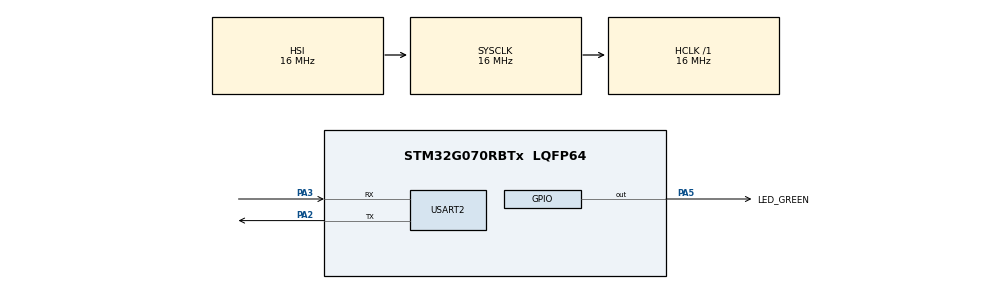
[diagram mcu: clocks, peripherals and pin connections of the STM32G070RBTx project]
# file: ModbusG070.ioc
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FREERTOS.Tasks01=defaultTask,24,128,StartDefaultTask,Default,NULL,Dynamic,NULL,NULL
FREERTOS.configUSE_NEWLIB_REENTRANT=1
Mcu.Family=STM32G0
Mcu.Name=STM32G070RBTx
Mcu.Package=LQFP64
NVIC.TIM17_IRQn=true\:3\:0\:false\:false\:true\:false\:false\:true\:true
NVIC.TimeBase=TIM17_IRQn
NVIC.TimeBaseIP=TIM17
NVIC.USART2_IRQn=true\:3\:0\:false\:false\:true\:true\:true\:true\:true
PA13.GPIO_Label=TMS
PA13.Mode=Serial_Wire
PA13.Signal=SYS_SWDIO
PA14-BOOT0.GPIO_Label=TCK
PA14-BOOT0.Mode=Serial_Wire
PA14-BOOT0.Signal=SYS_SWCLK
PA2.GPIO_PuPd=GPIO_PULLUP
PA2.Mode=Asynchronous
PA2.Signal=USART2_TX
PA3.GPIO_PuPd=GPIO_PULLUP
PA3.Mode=Asynchronous
PA3.Signal=USART2_RX
PA5.GPIO_Label=LED_GREEN
PA5.GPIO_Speed=GPIO_SPEED_FREQ_HIGH
PA5.Signal=GPIO_Output
PC13.Mode=SYS_WakeUp1
PC13.Signal=SYS_WKUP2
PC14-OSC32_IN\ (PC14).Mode=LSE-External-Oscillator
PC14-OSC32_IN\ (PC14).Signal=RCC_OSC32_IN
PC15-OSC32_OUT\ (PC15).Mode=LSE-External-Oscillator
PC15-OSC32_OUT\ (PC15).Signal=RCC_OSC32_OUT
PF0-OSC_IN\ (PF0).GPIO_Label=MCO
PF0-OSC_IN\ (PF0).Mode=HSE-External-Clock-Source
PF0-OSC_IN\ (PF0).Signal=RCC_OSC_IN
ProjectManager.HeapSize=0x200
ProjectManager.StackSize=0x400
ProjectManager.TargetToolchain=STM32CubeIDE
RCC.AHBFreq_Value=16000000
RCC.CortexFreq_Value=16000000
RCC.EXTERNAL_CLOCK_VALUE=12288000
RCC.HCLKFreq_Value=16000000
RCC.HSE_VALUE=8000000
RCC.HSI_VALUE=16000000
RCC.SYSCLKFreq_VALUE=16000000
RCC.VCOOutputFreq_Value=128000000
USART2.VirtualMode-Asynchronous=VM_ASYNC
USART2.WordLength=WORDLENGTH_8B
VP_FREERTOS_VS_CMSIS_V2.Mode=CMSIS_V2
VP_SYS_VS_DBSignals.Mode=DisableDeadBatterySignals
VP_SYS_VS_tim17.Mode=TIM17
board=NUCLEO-G070RB

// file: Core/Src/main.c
/* USER CODE BEGIN Header */
/**
  ******************************************************************************
  * @file           : main.c
  * @brief          : Main program body
  ******************************************************************************
  * @attention
  *
  * Copyright (c) 2024 STMicroelectronics.
  * All rights reserved.
  *
  * This software is licensed under terms that can be found in the LICENSE file
  * in the root directory of this software component.
  * If no LICENSE file comes with this software, it is provided AS-IS.
  *
  ******************************************************************************
  */
/* USER CODE END Header */
#include "main.h"
#include "cmsis_os.h"
#include "usart.h"
#include "gpio.h"

/* USER CODE BEGIN Includes */
#include "Modbus.h"
/* USER CODE END Includes */

/* USER CODE BEGIN PV */
modbusHandler_t ModbusH;
uint16_t ModbusDATA[8];
/* USER CODE END PV */

void SystemClock_Config(void);
void MX_FREERTOS_Init(void);

int main(void)
{

  /* MCU Configuration--------------------------------------------------------*/

  /* Reset of all peripherals, Initializes the Flash interface and the Systick. */
  HAL_Init();

  /* Configure the system clock */
  SystemClock_Config();

  /* Initialize all configured peripherals */
  MX_GPIO_Init();
  MX_USART2_UART_Init();
  /* USER CODE BEGIN 2 */

  //Modbus Slave initialization

  ModbusH.uModbusType = MB_SLAVE;
  ModbusH.port =  &huart2;
  ModbusH.u8id = 1; // For master it must be 0
  ModbusH.u16timeOut = 1000;
  ModbusH.EN_Port = NULL;
  ModbusH.EN_Port = NULL;
  ModbusH.EN_Pin = 0;
  ModbusH.u16regs = ModbusDATA;
  ModbusH.u16regsize= sizeof(ModbusDATA)/sizeof(ModbusDATA[0]);
  ModbusH.xTypeHW = USART_HW;

  //Initialize Modbus library
  ModbusInit(&ModbusH);
  //Start capturing traffic on serial Port
  ModbusStart(&ModbusH);

  /* USER CODE END 2 */

  /* Init scheduler */
  osKernelInitialize();

  /* Call init function for freertos objects (in freertos.c) */
  MX_FREERTOS_Init();

  /* Start scheduler */
  osKernelStart();

  /* We should never get here as control is now taken by the scheduler */
  /* Infinite loop */
  while (1)
  {

  }
}

void SystemClock_Config(void)
{
  RCC_OscInitTypeDef RCC_OscInitStruct = {0};
  RCC_ClkInitTypeDef RCC_ClkInitStruct = {0};

  /** Configure the main internal regulator output voltage
  */
  HAL_PWREx_ControlVoltageScaling(PWR_REGULATOR_VOLTAGE_SCALE1);

  /** Initializes the RCC Oscillators according to the specified parameters
  * in the RCC_OscInitTypeDef structure.
  */
  RCC_OscInitStruct.OscillatorType = RCC_OSCILLATORTYPE_HSI;
  RCC_OscInitStruct.HSIState = RCC_HSI_ON;
  RCC_OscInitStruct.HSIDiv = RCC_HSI_DIV1;
  RCC_OscInitStruct.HSICalibrationValue = RCC_HSICALIBRATION_DEFAULT;
  RCC_OscInitStruct.PLL.PLLState = RCC_PLL_NONE;
  if (HAL_RCC_OscConfig(&RCC_OscInitStruct) != HAL_OK)
  {
    Error_Handler();
  }

  /** Initializes the CPU, AHB and APB buses clocks
  */
  RCC_ClkInitStruct.ClockType = RCC_CLOCKTYPE_HCLK|RCC_CLOCKTYPE_SYSCLK
                              |RCC_CLOCKTYPE_PCLK1;
  RCC_ClkInitStruct.SYSCLKSource = RCC_SYSCLKSOURCE_HSI;
  RCC_ClkInitStruct.AHBCLKDivider = RCC_SYSCLK_DIV1;
  RCC_ClkInitStruct.APB1CLKDivider = RCC_HCLK_DIV1;

  if (HAL_RCC_ClockConfig(&RCC_ClkInitStruct, FLASH_LATENCY_0) != HAL_OK)
  {
    Error_Handler();
  }
}

void HAL_TIM_PeriodElapsedCallback(TIM_HandleTypeDef *htim)
{
  if (htim->Instance == TIM17) {
    HAL_IncTick();
  }
}

void Error_Handler(void)
{
  __disable_irq();
  while (1)
  {
  }
}

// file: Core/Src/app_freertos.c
/* USER CODE BEGIN Header */
/**
  ******************************************************************************
  * File Name          : app_freertos.c
  * Description        : Code for freertos applications
  ******************************************************************************
  * @attention
  *
  * Copyright (c) 2024 STMicroelectronics.
  * All rights reserved.
  *
  * This software is licensed under terms that can be found in the LICENSE file
  * in the root directory of this software component.
  * If no LICENSE file comes with this software, it is provided AS-IS.
  *
  ******************************************************************************
  */
/* USER CODE END Header */

#include "FreeRTOS.h"
#include "task.h"
#include "main.h"
#include "cmsis_os.h"

/* Definitions for defaultTask */
osThreadId_t defaultTaskHandle;
const osThreadAttr_t defaultTask_attributes = {
  .name = "defaultTask",
  .priority = (osPriority_t) osPriorityNormal,
  .stack_size = 128 * 4
};

void StartDefaultTask(void *argument);

void MX_FREERTOS_Init(void); /* (MISRA C 2004 rule 8.1) */

void MX_FREERTOS_Init(void) {

  /* Create the thread(s) */
  /* creation of defaultTask */
  defaultTaskHandle = osThreadNew(StartDefaultTask, NULL, &defaultTask_attributes);

}

void StartDefaultTask(void *argument)
{
  for(;;)
  {
    osDelay(1);
  }
}
